# AT90PWM161 register map
Vendor: Atmel; File version: 1.0
CPU: other r0p0, little endian, no MPU, no FPU, 4 interrupt priority bits
Registers are 8-bit, read-write, reset 0x0 unless marked. A register's access mark holds for its fields unless they carry their own. Offsets are from the block's base; [hi:lo] are bit positions; {n}, {i} and the like mark numbered series.

## ADC — Analog-to-Digital Converter
Base 0x00000026
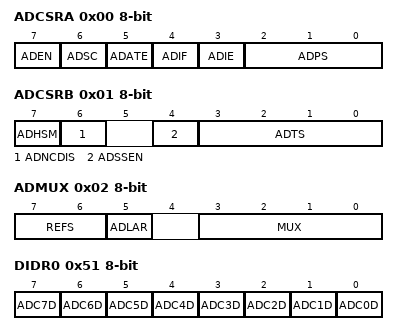
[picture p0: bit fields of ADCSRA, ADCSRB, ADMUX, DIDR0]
0x00 ADCSRA — The ADC Control and Status register
  [7] ADEN — ADC Enable
  [6] ADSC — ADC Start Conversion
  [5] ADATE — ADC Auto Trigger Enable
  [4] ADIF — ADC Interrupt Flag
  [3] ADIE — ADC Interrupt Enable
  [2:0] ADPS — ADC Prescaler Select Bits
0x01 ADCSRB — ADC Control and Status Register B
  [7] ADHSM — ADC High Speed Mode
  [6] ADNCDIS — ADC Noise Canceller Disable
  [4] ADSSEN — ADC Single Shot Enable on PSC's Synchronisation Signals
  [3:0] ADTS — ADC Auto Trigger Sources
    0=Free Running mode; 1=Analog Comparator; 2=External Interrupt Request 0; 3=Timer/Counter0 Compare Match A; 4=Timer/Counter0 Overflow; 5=Timer/Counter1 Compare Match B; 6=Timer/Counter1 Overflow; 7=Timer/Counter1 Capture Event; 8=PSC0ASY Event; 9=PSC1ASY Event; 10=PSC2ASY Event; 11=Analog comparator 1; 12=Analog comparator 2
0x02 ADMUX — The ADC multiplexer Selection Register
  [7:6] REFS — Reference Selection Bits
    0=AREF, Internal Vref turned off; 1=AVCC with external capacitor at AREF pin; 3=Internal 2.56V Voltage Reference with external capacitor at AREF pin
  [5] ADLAR — Left Adjust Result
  [3:0] MUX — Analog Channel and Gain Selection Bits
0x26 ADC 16-bit (reset mask 0xFF) — ADC Data Register Bytes
0x51 DIDR0 — Digital Input Disable Register 0
  [7] ADC7D
  [6] ADC6D — ADC7 Digital input Disable
  [n] ADC{n}D (n=0..5) — ADC{n} Digital input Disable
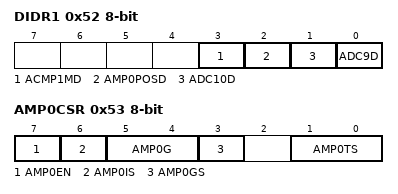
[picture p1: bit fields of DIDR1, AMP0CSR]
0x52 DIDR1 — Digital Input Disable Register 0
  [3] ACMP1MD, [2] AMP0POSD, [1] ADC10D, [0] ADC9D
0x53 AMP0CSR
  [7] AMP0EN, [6] AMP0IS, [5:4] AMP0G, [3] AMP0GS, [1:0] AMP0TS

## BOOT_LOAD — Bootloader
Base 0x00000057
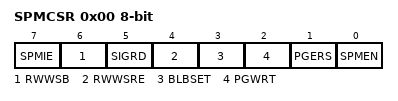
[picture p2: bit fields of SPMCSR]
0x00 SPMCSR — Store Program Memory Control Register
  [7] SPMIE — SPM Interrupt Enable
  [6] RWWSB — Read While Write Section Busy
  [5] SIGRD — Signature Row Read
  [4] RWWSRE — Read While Write section read enable
  [3] BLBSET — Boot Lock Bit Set
  [2] PGWRT — Page Write
  [1] PGERS — Page Erase
  [0] SPMEN — Store Program Memory Enable

## CPU — CPU Registers
Base 0x00000039
{0x0+i} GPIOR{i} (i=0..2) — General Purpose IO Register {i}
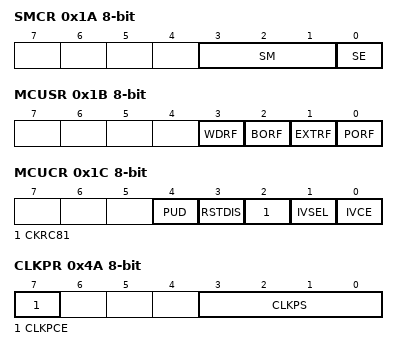
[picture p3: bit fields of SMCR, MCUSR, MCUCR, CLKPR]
0x1A SMCR — Sleep Mode Control Register
  [3:1] SM — Sleep Mode Select bits
    0=IDLE; 1=ADC (ADC Noise Reduction (If Available)); 2=PDOWN (Power Down); 6=STDBY (Standby)
  [0] SE — Sleep Enable
0x1B MCUSR — MCU Status Register
  [3] WDRF — Watchdog Reset Flag
  [2] BORF — Brown-out Reset Flag
  [1] EXTRF — External Reset Flag
  [0] PORF — Power-on reset flag
0x1C MCUCR — MCU Control Register
  [4] PUD — Pull-up disable
  [3] RSTDIS — Reset Pin Disable
  [2] CKRC81 — Frequency Selection of the Calibrated RC Oscillator
  [1] IVSEL — Interrupt Vector Select
  [0] IVCE — Interrupt Vector Change Enable
0x47 BGCRR — BandGap Resistor Calibration Register
  [3:0] BGCR
0x48 BGCCR — BandGap Current Calibration Register
  [3:0] BGCC
0x4A CLKPR
  [7] CLKPCE
  [3:0] CLKPS
    0=1; 1=2; 2=4; 3=8; 4=16; 5=32; 6=64; 7=128; 8=256
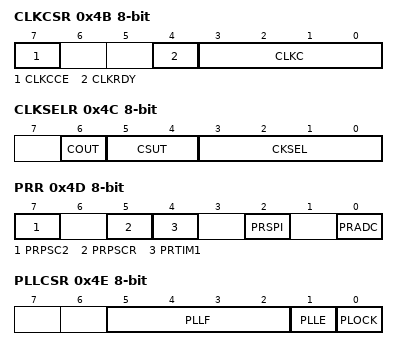
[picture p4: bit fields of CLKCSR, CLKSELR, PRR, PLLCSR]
0x4B CLKCSR
  [7] CLKCCE — Clock Control Change Enable
  [4] CLKRDY — Clock Ready Flag
  [3:0] CLKC — Clock Control
0x4C CLKSELR
  [6] COUT — Clock OUT
  [5:4] CSUT — Clock Start up Time
  [3:0] CKSEL — Clock Source Select
0x4D PRR — Power Reduction Register
  [7] PRPSC2 — Power Reduction PSC2
  [5] PRPSCR — Power Reduction PSC0
  [4] PRTIM1 — Power Reduction Timer/Counter1
  [2] PRSPI — Power Reduction Serial Peripheral Interface
  [0] PRADC — Power Reduction ADC
0x4E PLLCSR — PLL Control And Status Register
  [5:2] PLLF
  [1] PLLE — PLL Enable
  [0] PLOCK — PLL Lock Detector
0x4F OSCCAL — Oscillator Calibration Value
  [7:0] OSCCAL — Oscillator Calibration

## DAC — Digital-to-Analog Converter
Base 0x00000058
0x00 DACL — DAC Data Register Low Byte
  [7:0] DACL — DAC Data Register Low Byte Bits
0x01 DACH — DAC Data Register High Byte
  [7:0] DACH — DAC Data Register High Byte Bits
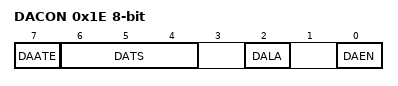
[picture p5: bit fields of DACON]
0x1E DACON — DAC Control Register
  [7] DAATE — DAC Auto Trigger Enable Bit
  [6:4] DATS — DAC Trigger Selection Bits
    0=Analog Comparator 0; 1=Analog Comparator 1; 2=External Interrupt Request 0; 3=Timer/Counter0 Compare Match A; 4=Timer/Counter0 Overflow; 5=Timer/Counter1 Compare Match B; 6=Timer/Counter1 Overflow; 7=Timer/Counter1 Capture Event
  [2] DALA — DAC Left Adjust
  [0] DAEN — DAC Enable Bit
